# STM32WB55x register map
File version: 1.0
CPU: CM4 r0p1, little endian, 4 interrupt priority bits
Registers are 32-bit, read-write, reset 0x0 unless marked. A register's access mark holds for its fields unless they carry their own. Offsets are from the block's base; [hi:lo] are bit positions; {n}, {i} and the like mark numbered series; 'fields as' and 'values as' point back to an identical list.

## TIM16
Base 0x40014400
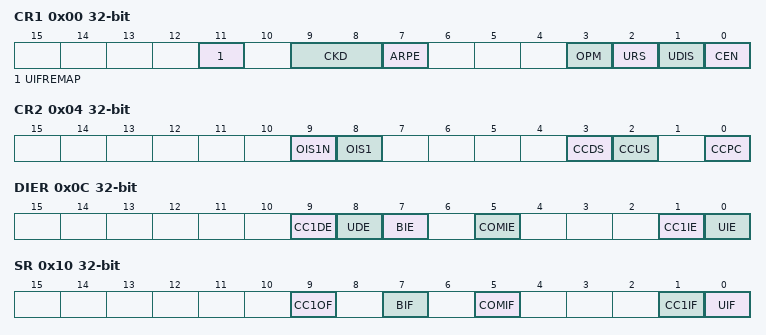
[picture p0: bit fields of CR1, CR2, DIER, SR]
0x00 CR1
  [11] UIFREMAP, [9:8] CKD, [7] ARPE, [3] OPM, [2] URS, [1] UDIS, [0] CEN
0x04 CR2
  [9] OIS1N, [8] OIS1, [3] CCDS, [2] CCUS, [0] CCPC
0x0C DIER
  [9] CC1DE, [8] UDE, [7] BIE, [5] COMIE, [1] CC1IE, [0] UIE
0x10 SR
  [9] CC1OF, [7] BIF, [5] COMIF, [1] CC1IF, [0] UIF
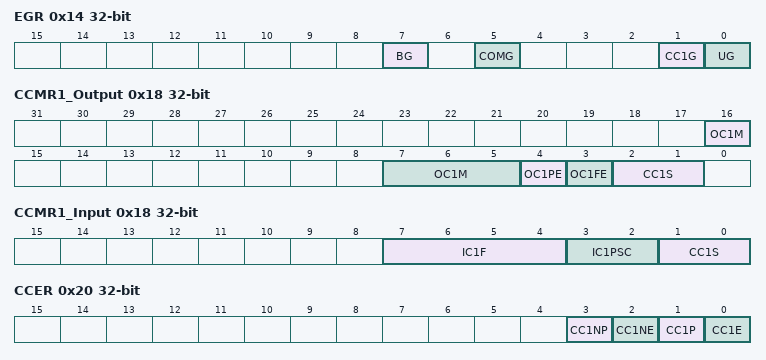
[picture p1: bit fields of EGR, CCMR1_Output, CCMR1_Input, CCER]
0x14 EGR
  [7] BG, [5] COMG, [1] CC1G, [0] UG
0x18 CCMR1_Output
  [16] OC1M, [7:5] OC1M, [4] OC1PE, [3] OC1FE, [2:1] CC1S
0x18 CCMR1_Input
  [7:4] IC1F, [3:2] IC1PSC, [1:0] CC1S
0x20 CCER
  [3] CC1NP, [2] CC1NE, [1] CC1P, [0] CC1E
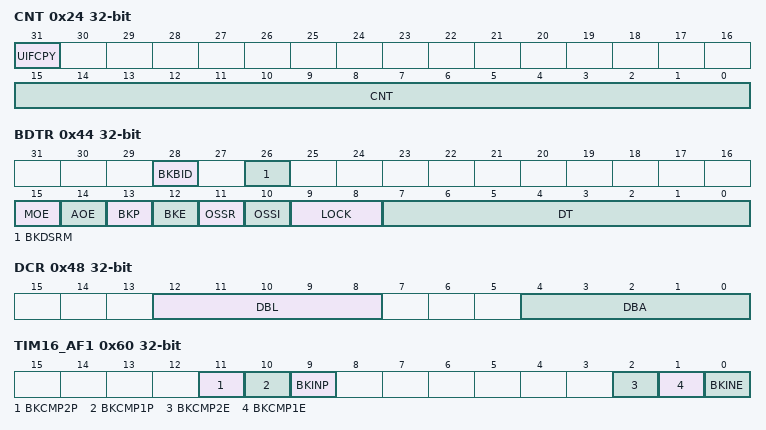
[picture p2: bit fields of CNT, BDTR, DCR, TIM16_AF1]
0x24 CNT
  [31] UIFCPY, [15:0] CNT
0x28 PSC
  [15:0] PSC
0x2C ARR
  [15:0] ARR
0x30 RCR
  [7:0] REP
0x34 CCR1
  [15:0] CCR1
0x44 BDTR
  [28] BKBID, [26] BKDSRM, [15] MOE, [14] AOE, [13] BKP, [12] BKE, [11] OSSR, [10] OSSI, [9:8] LOCK, [7:0] DT
0x48 DCR
  [12:8] DBL, [4:0] DBA
0x4C DMAR
  [15:0] DMAB
0x50 TIM16_OR1
  [1:0] TI1_RMP
0x50 TIM17_OR1
  [1:0] TI1_RMP
0x60 TIM16_AF1
  [11] BKCMP2P, [10] BKCMP1P, [9] BKINP, [2] BKCMP2E, [1] BKCMP1E, [0] BKINE
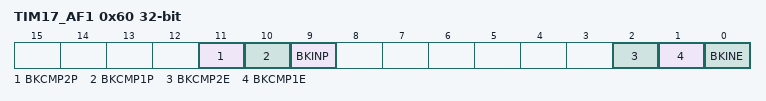
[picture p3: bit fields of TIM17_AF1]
0x60 TIM17_AF1
  fields as TIM16_AF1
0x68 TIM16_TISEL
  [3:0] TI1SEL
0x68 TIM17_TISEL
  [3:0] TI1SEL

## TIM17
Base 0x40014800
Registers as TIM16 (with TIM16 read as TIM17), without TIM17_OR1, TIM17_AF1, TIM17_TISEL; these are added or differ:
0x50 TIM16_OR1
  [1:0] TI1_RMP
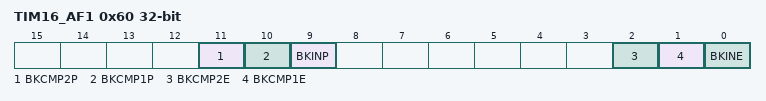
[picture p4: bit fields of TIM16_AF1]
0x60 TIM16_AF1
  [11] BKCMP2P, [10] BKCMP1P, [9] BKINP, [2] BKCMP2E, [1] BKCMP1E, [0] BKINE
0x68 TIM16_TISEL
  [3:0] TI1SEL

## LPTIM1
Base 0x40007C00
Same registers: LPTIM2 0x40008000
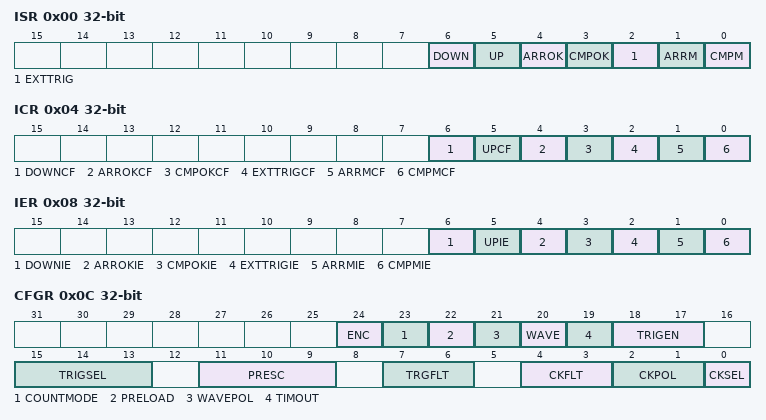
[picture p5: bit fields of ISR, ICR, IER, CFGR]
0x00 ISR
  [6] DOWN, [5] UP, [4] ARROK, [3] CMPOK, [2] EXTTRIG, [1] ARRM, [0] CMPM
0x04 ICR
  [6] DOWNCF, [5] UPCF, [4] ARROKCF, [3] CMPOKCF, [2] EXTTRIGCF, [1] ARRMCF, [0] CMPMCF
0x08 IER
  [6] DOWNIE, [5] UPIE, [4] ARROKIE, [3] CMPOKIE, [2] EXTTRIGIE, [1] ARRMIE, [0] CMPMIE
0x0C CFGR
  [24] ENC, [23] COUNTMODE, [22] PRELOAD, [21] WAVEPOL, [20] WAVE, [19] TIMOUT, [18:17] TRIGEN, [15:13] TRIGSEL, [11:9] PRESC, [7:6] TRGFLT, [4:3] CKFLT, [2:1] CKPOL, [0] CKSEL
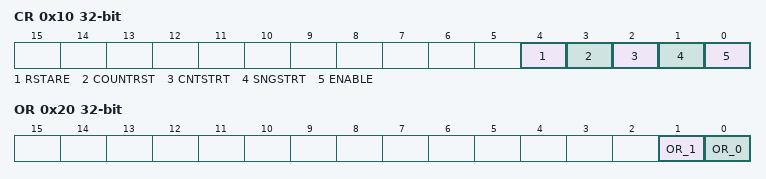
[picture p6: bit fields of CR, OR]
0x10 CR
  [4] RSTARE, [3] COUNTRST, [2] CNTSTRT, [1] SNGSTRT, [0] ENABLE
0x14 CMP
  [15:0] CMP
0x18 ARR
  [15:0] ARR
0x1C CNT
  [15:0] CNT
0x20 OR
  [1] OR_1, [0] OR_0

## NVIC — Nested Vectored Interrupt Controller
Base 0xE000E000
0x04 ICTR ro — Interrupt Controller Type Register
  [3:0] INTLINESNUM — Total number of interrupt lines in groups
{0x100+4i} ISER{i} (i=0..2) — Interrupt Set-Enable Register
  [31:0] SETENA
{0x180+4i} ICER{i} (i=0..2) — Interrupt Clear-Enable Register
  [31:0] CLRENA
{0x200+4i} ISPR{i} (i=0..2) — Interrupt Set-Pending Register
  [31:0] SETPEND
{0x280+4i} ICPR{i} (i=0..2) — Interrupt Clear-Pending Register
  [31:0] CLRPEND
{0x300+4i} IABR{i} ro (i=0..2) — Interrupt Active Bit Register
  [31:0] ACTIVE
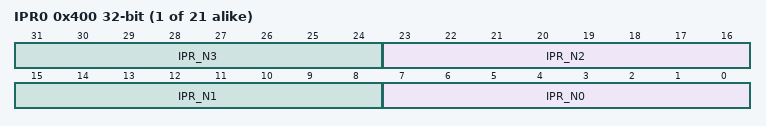
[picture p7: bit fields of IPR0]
{0x400+4i} IPR{i} (i=0..20) — Interrupt Priority Register
  [8n+7:8n] IPR_N{n} (n=0..3)
0xF00 STIR wo — Software Triggered Interrupt Register
  [8:0] INTID — interrupt to be triggered

## DBGMCU — MCU debug component
Base 0xE0042000
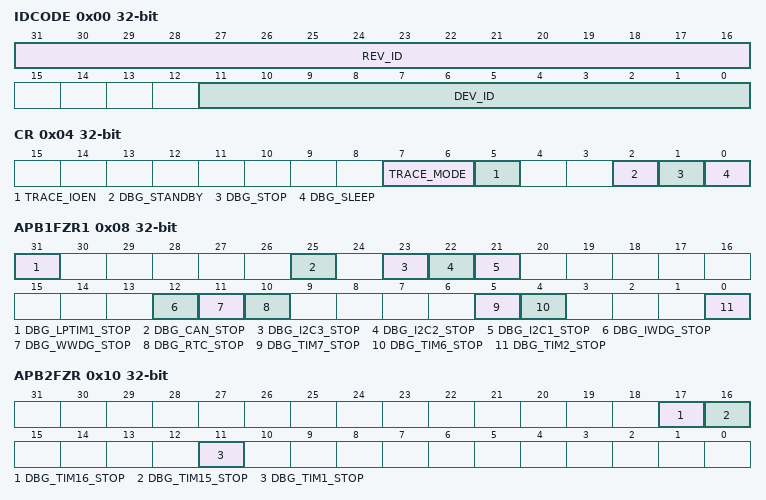
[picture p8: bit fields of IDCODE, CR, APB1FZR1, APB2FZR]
0x00 IDCODE ro — DBGMCU_IDCODE
  [31:16] REV_ID — Revision identifie
  [11:0] DEV_ID — Device identifier
0x04 CR — Debug MCU configuration register
  [7:6] TRACE_MODE — Trace pin assignment control
  [5] TRACE_IOEN — Trace pin assignment control
  [2] DBG_STANDBY — Debug Standby mode
  [1] DBG_STOP — Debug Stop mode
  [0] DBG_SLEEP — Debug Sleep mode
0x08 APB1FZR1 — Debug MCU APB1 freeze register1
  [31] DBG_LPTIM1_STOP — LPTIM1 counter stopped when core is halted
  [25] DBG_CAN_STOP — bxCAN stopped when core is halted
  [23] DBG_I2C3_STOP — I2C3 SMBUS timeout counter stopped when core is halted
  [22] DBG_I2C2_STOP — I2C2 SMBUS timeout counter stopped when core is halted
  [21] DBG_I2C1_STOP — I2C1 SMBUS timeout counter stopped when core is halted
  [12] DBG_IWDG_STOP — Independent watchdog counter stopped when core is halted
  [11] DBG_WWDG_STOP — Window watchdog counter stopped when core is halted
  [10] DBG_RTC_STOP — RTC counter stopped when core is halted
  [5] DBG_TIM7_STOP — TIM7 counter stopped when core is halted
  [4] DBG_TIM6_STOP — TIM6 counter stopped when core is halted
  [0] DBG_TIM2_STOP — TIM2 counter stopped when core is halted
0x0C APB1FZR2 — Debug MCU APB1 freeze register 2
  [5] DBG_LPTIM2_STOP — LPTIM2 counter stopped when core is halted
0x10 APB2FZR — Debug MCU APB2 freeze register
  [17] DBG_TIM16_STOP — TIM16 counter stopped when core is halted
  [16] DBG_TIM15_STOP — TIM15 counter stopped when core is halted
  [11] DBG_TIM1_STOP — TIM1 counter stopped when core is halted
